# BlueNRG2 register map
Vendor: STMicroelectronics; Series: BlueNRG1; File version: 1.0.0
CPU: CM0 r0p0, little endian, no MPU, no FPU, 2 interrupt priority bits
Registers are 32-bit, read-write, reset 0x0 unless marked. A register's access mark holds for its fields unless they carry their own. Offsets are from the block's base; [hi:lo] are bit positions; {n}, {i} and the like mark numbered series; 'fields as' and 'values as' point back to an identical list.

## FLASH — Flash Controller
Base 0x40100000
0x00 COMMAND 16-bit — Commands for the module
0x04 CONFIG 16-bit — Configure the wrapper
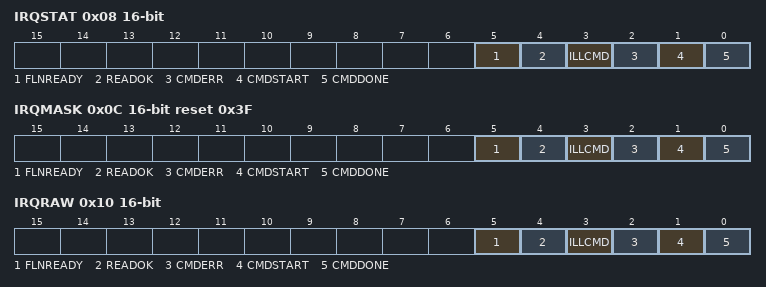
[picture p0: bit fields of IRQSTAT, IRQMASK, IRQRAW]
0x08 IRQSTAT 16-bit — Flash status interrupt (masked)
  [all] fields
    1=IRQ_PENDING; 0=IRQ_NOT_PENDING
  [5] FLNREADY — Flash not ready (sleep). 1: clear the interrupt pending bit.
  [4] READOK — Mass read was OK. 1: clear the interrupt pending bit.
  [3] ILLCMD — Illegal command written. 1: clear the interrupt pending bit.
  [2] CMDERR — Command written while BUSY. 1: clear the interrupt pending bit.
  [1] CMDSTART — Command is started. 1: clear the interrupt pending bit.
  [0] CMDDONE — Command is done. 1: clear the interrupt pending bit.
0x0C IRQMASK 16-bit reset 0x3F — Mask for interrupts
  [all] fields
    1=IRQ_PENDING; 0=IRQ_NOT_PENDING
  [5] FLNREADY — Flash not ready (sleep).
  [4] READOK — Mass read was OK.
  [3] ILLCMD — Illegal command written
  [2] CMDERR — Command written while BUSY
  [1] CMDSTART — Command is started.
  [0] CMDDONE — Command is done.
0x10 IRQRAW 16-bit — Status interrupts (unmasked)
  fields as IRQMASK
0x14 SIZE 16-bit ro — Indicates the last usable address of the main Flash
0x18 ADDRESS — Address for programming Flash, will auto-increment
0x24 LFSRVAL ro reset 0xFFFFFFFF — LFSR register needed for check after MASS READ command
0x28 TIMETRIM1 reset 0xB061515 — Trimming values for Flash erase/modify sequences
0x2C TIMETRIM2 reset 0xB156506 — Trimming values for Flash erase/modify sequences
0x30 TIMETRIM3 reset 0x11 — Trimming values for Flash wake-up sequence
{0x40+4i} DATA{i} reset 0xFFFFFFFF (i=0..3) — Program cycle data

## SYSTEM_CTRL — System controller
Base 0x40200000
0x00 WKP_IO_IS 8-bit (reset mask 0x1F) — Level selection for wakeup IO (1 bit for IO) IO[13:9].<ul><li>0: The system wakes up when IO is low.</li><li>1: The system wakes up when IO is high.</li></ul>
0x04 WKP_IO_IE 8-bit reset 0x7 (reset mask 0x1F) — Enables the IO that wakes up the device (1 bit for IO) IO[13:9].<ul><li>0: The wakes up feature on the IO is disabled.</li><li>1: The wakes up feature on the IO is enabled.</li></ul>
0x08 CTRL 8-bit — XO frequency indication to provide by the application
  [0] MHZ32_SEL — Indicates the crystal frequency used in the application.<ul><li>0: The 16 MHz is selected.</li><li>1: The 32 MHz is selected.</li></ul>
    0=MHz16 (16 MHz is selected); 1=MHz32 (32 MHz is selected)
0x0C SLEEPIO_OEN 8-bit reset 0x7 (reset mask 0x1F) — IO output enable register for low power modes. It is 1 bit for IO: bit0 for IO9, bit1 for IO10, bit2 for IO9.<ul><li>0: IO output disabled.</li><li>1: IO output is enabled.</li></ul>
0x10 SLEEPIO_OUT 8-bit (reset mask 0x1F) — IO data output value register for low power modes. It is 1 bit for IO: bit0 for IO9, bit1 for IO10, bit2 for IO9.<ul><li>0: put the IO low.</li><li>1: put the IO high.</li></ul>
0x14 SLEEPIO_DS 8-bit (reset mask 0x1F) — IO drive strength control register for low power modes. It is 1 bit for IO: bit0 for IO9, bit1 for IO10, bit2 for IO9.<ul><li>0: drive up to 2 mA.</li><li>1: drive up to 4 mA.</li></ul>
0x18 SLEEPIO_PE 8-bit (reset mask 0x1F) — IO pull enable register for low power modes. It is 1 bit for IO: bit0 for IO9, bit1 for IO10, bit2 for IO9.<ul><li>0: pull disabled.</li><li>1: pull enabled.</li></ul>

## WDG — Watchdog
Base 0x40700000
0x00 LR reset 0xFFFFFFFF — Watchdog Load Register
  [31:0] LOAD range 1..0xFFFFFFFF — Watchdog load value. Value from which the counter is to decrement. When this register is written to, the count is immediately restarted from the new value.
0x04 VAL ro reset 0xFFFFFFFF — Watchdog Value Register
  [31:0] WDTVAL — Watchdog load value. When read, returns the current value of the decrementing watchdog counter. A write has no effect.
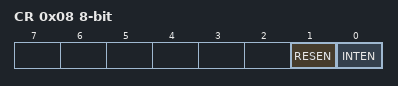
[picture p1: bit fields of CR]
0x08 CR 8-bit — Watchdog Control Register
  [1] RESEN — Watchdog reset enable. Enable the watchdog reset output:<ul><li>0: watchdog reset is disabled.</li><li>1: watchdog reset is enabled.</li></ul>
    0=DISABLE (Disable watchdog reset); 1=ENABLE (Enable watchdog reset)
  [0] INTEN — Watchdog interrupt enable. Enable the interrupt event:<ul><li>0: watchdog interrupt is disabled.</li><li>1: watchdog interrupt is enabled.</li></ul>
    0=DISABLE (Disable watchdog interrupt); 1=ENABLE (Enable watchdog interrupt)
0x0C ICR write-clears — Watchdog Interrupt Clear Register
  [31:0] WDTICLR — Watchdog interrupt enable:<ul><li>Writing any value will clear the watchdog interrupt and reloads the counter from the LR register.</li><li>A read returns zero.</li></ul>
0x10 RIS 8-bit ro — Watchdog Raw Interrupt Status Register
  [0] RIS — Watchdog raw interrupt status bit. Reflects the status of the interrupt status from the watchdog:<ul><li>0: watchdog interrupt is not active.</li><li>1: watchdog interrupt is active.</li></ul>Read-only bit. A write has no effect.
    0=IRQ_NOT_PENDING (Watchdog interrupt is not active); 1=IRQ_PENDING (Watchdog interrupt is active)
0x14 MIS 8-bit ro — Watchdog Masked Interrupt Status Register
  [0] MIS — Watchdog masked interrupt status bit. Masked value of watchdog interrupt status:<ul><li>0: watchdog interrupt is not active.</li><li>1: watchdog interrupt is active.</li></ul>Read-only bit. A write has no effect.
    0=IRQ_NOT_PENDING (Watchdog interrupt masked is not active); 1=IRQ_PENDING (Watchdog interrupt masked is active)
0xC00 LOCK — Watchdog Lock Register
  [31:0] LOCKVAL — Watchdog lock value. When read, returns the lock status:<ul><li>0: Write access to all watchdog other registers is enabled.</li><li>1: Write access to all watchdog other registers is disabled.</li></ul>When written, allows enabling or disabling write access to all other watchdog registers:<ul><li>Writing 0x1ACCE551: Write access to all other registers is enabled.</li><li>Writing any other value: Write access to all other registers is disabled.</li></ul>
